# MDR1986VK214 register map
Vendor: Milandr; Series: ARMCM0; File version: 2.0
CPU: CM0 r0p0, little endian, no MPU, no FPU, 2 interrupt priority bits
Registers are 32-bit, read-write, reset 0x0 unless marked. A register's access mark holds for its fields unless they carry their own. Offsets are from the block's base; [hi:lo] are bit positions; {n}, {i} and the like mark numbered series; 'fields as' and 'values as' point back to an identical list.

## MDR_Power — Power Detector
Base 0x40058000
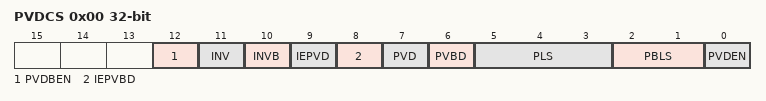
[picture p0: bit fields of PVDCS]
0x00 PVDCS — Control-Status register
  [12] PVDBEN — Enable BUcc detector
    0=Off (Disabled); 1=On (Enabled)
  [11] INV — PVD event on BUcc lt PBLS
    0=Off (Disabled); 1=On (Enabled)
  [10] INVB — PVBD event on BUcc lt PBLS
    0=Off (Disabled); 1=On (Enabled)
  [9] IEPVD — Enable IRQ by PVD event
    0=Off (Disabled); 1=On (Enabled)
  [8] IEPVBD — Enable IRQ by PVBD event
    0=Off (Disabled); 1=On (Enabled)
  [7] PVD — Event on Ucc gt PLS
    0=Inactive (No Event); 1=Active (Event is active)
  [6] PVBD — Event on BUcc gt PBLS
    0=Inactive (No Event); 1=Active (Event is active)
  [5:3] PLS — Ucc compare level
    0=2v0 (Level of 2.0 volts); 1=2v2 (Level of 2.2 volts); 2=2v4 (Level of 2.4 volts); 3=2v6 (Level of 2.6 volts); 4=2v8 (Level of 2.8 volts); 5=3v0 (Level of 3.0 volts); 6=3v2 (Level of 3.2 volts); 7=3v4 (Level of 3.4 volts)
  [2:1] PBLS — BUcc compare level
    0=1v8 (Level of 1.8 volts); 1=2v2 (Level of 2.2 volts); 2=2v6 (Level of 2.6 volts); 3=3v0 (Level of 3.0 volts)
  [0] PVDEN — Enable Ucc detector
    0=Off (Disabled); 1=On (Enabled)
0x04 ResReg ro reset not defined — Reserved register
  [31:0] Value — blank

## MDR_WWDT — Window Watchdog Timer
Base 0x40048000
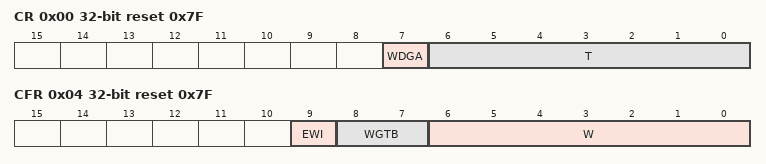
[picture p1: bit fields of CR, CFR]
0x00 CR reset 0x7F — WWDT Control register
  [7] WDGA — Enable
    0=Off (Disabled); 1=On (Enabled)
  [6:0] T — Counter
0x04 CFR reset 0x7F — WWDT Config register
  [9] EWI — Early Window Interrupt
    0=Off (Disabled IRQ on T=0x40); 1=On (Enabled IRQ on T=0x40)
  [8:7] WGTB — Clock Divider
    0=div1 (CLK = LSI/4096/1); 1=div2 (CLK = LSI/4096/2); 2=div4 (CLK = LSI/4096/4); 3=div8 (CLK = LSI/4096/8)
  [6:0] W — Window value
0x08 SR — WWDT Status register
  [0] EWIF — Early Window Flag
    0=Off (Event Off); 1=Onn (Event On)

## MDR_IWDT — Independent Watchdog Timer
Base 0x40050000
0x00 KR wo — Key register
  [15:0] KEY — Enable, start and reload control
0x04 PR — Clock Prescaler register
  [2:0] PR — Prescaler Register
    0=div4 (LSI div 4); 1=div8 (LSI div 8); 2=div16 (LSI div 16); 3=div32 (LSI div 32); 4=div64 (LSI div 64); 5=div128 (LSI div 128); 6=div256 (LSI div 256); 7=div256_1 (LSI div 256)
0x08 RLR reset 0xFFF — Reload Period Register
  [11:0] PRL — Timer Period Value
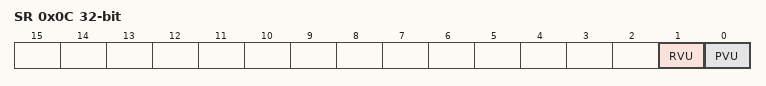
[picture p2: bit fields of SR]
0x0C SR ro — Status Regster
  [1] RVU — PRL busy
    0=Ready (PRL ready for write); 1=Busy (PRL busy)
  [0] PVU — PR busy
    0=Ready (PR ready for write); 1=Busy (PR busy)

## MDR_LCD_VK214 — LCD Display Controler
Base 0x40038000
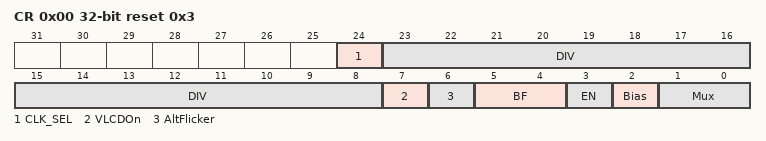
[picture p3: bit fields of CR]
0x00 CR reset 0x3 (reset mask 0xFFFFFF) — LCD Control register
  [24] CLK_SEL — Clock Select
    0=LSE (Clock from LSE); 1=LSI (Clock from LSI)
  [23:8] DIV — Clock div
  [7] VLCDOn — Select Vlcd power
    0=Internal source; 1=External source from pin PC2
  [6] AltFlicker — AlterFlicker
    0=byRegBF (Flicker according to BF); 1=byAlterMemory (Flicker according to alter memory)
  [5:4] BF — Flicker
    0=Off (Flicker Disabled); 1=2Hz (Flicker with 2 Hz); 2=1Hz (Flicker with 1 Hz); 3=0Hz5 (Flicker with 0.5 Hz)
  [3] EN — Enable
    0=Off (Disabled); 1=On (Enabled)
  [2] Bias — Bias Modes
    0=div3 (Bias 1/3); 1=div2 (Bias 1/2)
  [1:0] Mux — Multiplex select
    0=Static control; 1=Muxtiplexing 1:2; 2=Muxtiplexing 1:3; 3=Muxtiplexing 1:4
{0x0+4i} ROW{i} (i=1..4) (reset mask 0x3FFFFFFF) — Base memory data string
{0x10+4i} AROW{i} (i=1..4) (reset mask 0x3FFFFFFF) — Alter memory data string

## MDR_SSP1 — Synchronous Serial Port
Base 0x40000000
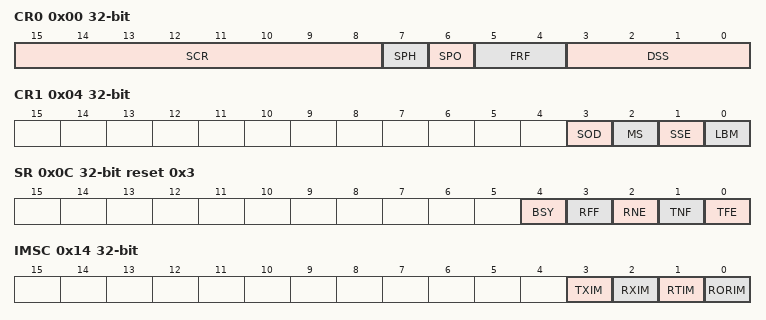
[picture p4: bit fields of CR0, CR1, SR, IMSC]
0x00 CR0 — Control Register 0
  [15:8] SCR — Signal CLock Rate
  [7] SPH — SPI Capture Clock Phase
    0=Leading (Capture data on leading edge); 1=Trailing (Capture data on trailing edge)
  [6] SPO — SPI Clock Polarity
    0=Idle_Low (Idle state is Low); 1=Idle_High (Idle state is High)
  [5:4] FRF — Frame Format
    0=SPI (Motorola SPI protocol); 1=SSI (Texas Instruments SSI protocol); 2=Microwire (National Semiconductor Microwire protocol)
  [3:0] DSS — Data Size Select
    {v}=bits_{v+1} (Word of {v+1} bits) (v=3..15)
0x04 CR1 — Control Register 1
  [3] SOD — Slave mode Output Disable
    0=SlaveTxEna (Slave mode transmit enable); 1=SlaveTxDis (Slave mode transmit disable)
  [2] MS — Master or Slave mode
    0=Master Mode; 1=Slave Mode
  [1] SSE — Synchronous Serial Enable
    0=Off (SSP Disable); 1=On (SSP Enable)
  [0] LBM — Loop Back Mode
    0=Normal operation; 1=LoopBack (TX send to RX test mode)
0x08 DR — FIFO_Rx and FIFO_Tx access
  [15:0] Data — Data value
0x0C SR ro reset 0x3 — Status Register
  [4] BSY — Transfer in progress
    0=Idle (FIFO_RX is Not Full); 1=Busy (Transfering)
  [3] RFF — FIFO_RX is Full
    0=RX_NotFull (FIFO_RX is Not Full); 1=RX_Full (FIFO_RX is Full)
  [2] RNE — FIFO_RX is Not Empty
    0=RX_NotEmpty (FIFO_RX is Empty); 1=RX_Empty (FIFO_RX is Not Empty)
  [1] TNF — FIFO_TX is Not Full
    0=TX_Full (FIFO_TX is Full); 1=TX_NotFull (FIFO_TX is Not Full)
  [0] TFE — FIFO_TX is Empty
    0=TX_NotEmpty (FIFO_TX is Not Empty); 1=TX_Empty (FIFO_TX is Empty)
0x10 CPSR — Clock Prescaller Register
  [7:0] CPSDVSR — Clock Prescaller
0x14 IMSC — IRQ Mask Set-Clear
  [3] TXIM — Enable IQR on FIFO_TX le 4 words
    0=NoEvent (Flag Inactive); 1=TX_HalfEmpty (Flag Active)
  [2] RXIM — Enable IQR on FIFO_RX ge 4 words
    0=NoEvent (Flag Inactive); 1=RX_HalfFull (Flag Active)
  [1] RTIM — Enable IQR on RX timeout for 32bits
    0=NoEvent (Flag Inactive); 1=RX_Timeout (Flag Active)
  [0] RORIM — Enable IRQ on FIFO_RX overrun
    0=NoEvent (Flag Inactive); 1=RX_Overrun (Flag Active)
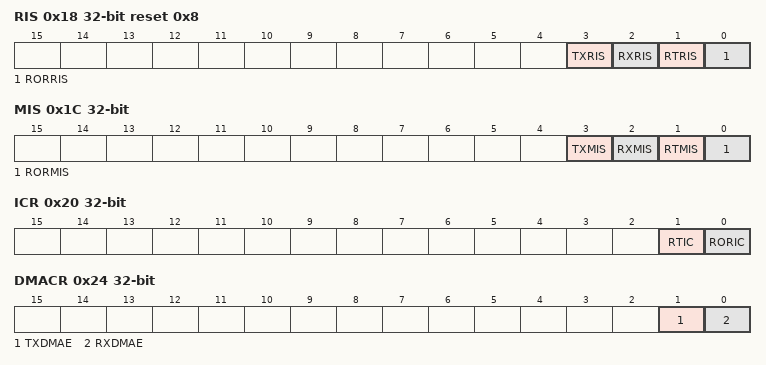
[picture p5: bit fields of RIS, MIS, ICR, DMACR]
0x18 RIS ro reset 0x8 — Raw Interupt Status
  [3] TXRIS — FIFO_TX le words
    0=NoEvent (Flag Inactive); 1=TX_HalfEmpty (Flag Active)
  [2] RXRIS — FIFO_RX gt words
    0=NoEvent (Flag Inactive); 1=RX_HalfFull (Flag Active)
  [1] RTRIS — RX timeout for 32bits
    0=NoEvent (Flag Inactive); 1=RX_Timeout (Flag Active)
  [0] RORRIS — FIFO_RX is overrun
    0=NoEvent (Flag Inactive); 1=RX_Overrun (Flag Active)
0x1C MIS ro — Masked Interupt Status
  [3] TXMIS — FIFO_TX le 4 words
    0=NoEvent (Flag Inactive); 1=TX_HalfEmpty (Flag Active)
  [2] RXMIS — FIFO_RX ge 4 words
    0=NoEvent (Flag Inactive); 1=RX_HalfFull (Flag Active)
  [1] RTMIS — RX timeout for 32bits
    0=NoEvent (Flag Inactive); 1=RX_Timeout (Flag Active)
  [0] RORMIS — FIFO_RX is overrun
    0=NoEvent (Flag Inactive); 1=RX_Overrun (Flag Active)
0x20 ICR wo — Interupt Clear Register
  [1] RTIC — Clear RX timeout flag
    0=Inactive (No action); 1=Clear Flag
  [0] RORIC — Clear FIFO_RX overrun flag
    0=Inactive (No action); 1=Clear Flag
0x24 DMACR — DMA Control Register
  [1] TXDMAE — Enable DMA by FIFO_TX not Full
    0=Disable DMA; 1=Enable DMA
  [0] RXDMAE — Enable DMA by FIFO_RX has data
    0=Disable DMA; 1=Enable DMA

## MDR_PORTA — GPIO Port Control
Base 0x40080000
Same registers: MDR_PORTB 0x40088000, MDR_PORTC 0x40090000
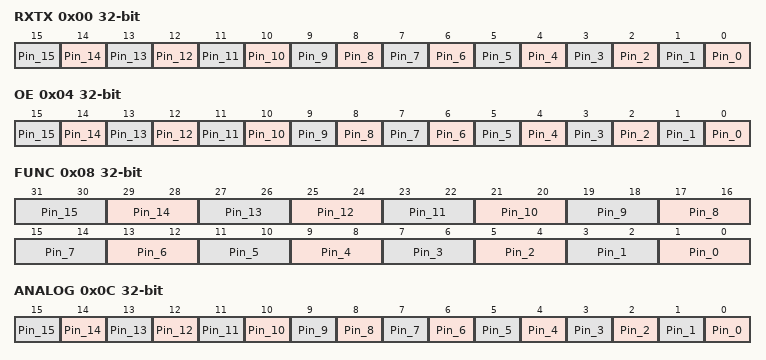
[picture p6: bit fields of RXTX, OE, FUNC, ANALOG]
0x00 RXTX (reset mask 0xFFFF) — GPIO Pin Data
  [n] Pin_{n} (n=0..15) — Pin data value
    0=Low (LOW Level Voltage); 1=HIGH Level Voltage
0x04 OE (reset mask 0xFFFF) — Output Enable Control
  [n] Pin_{n} (n=0..15) — Pin data direction
    0=IN (Input pin); 1=OUT (Output pin)
0x08 FUNC — Pin Functions in Digital mode
  [2n+1:2n] Pin_{n} (n=0..15) — Pin Digital Function
    0=Port (RXTX defined pin); 1=Main Periph defined pin; 2=Alter Periph defined pin; 3=Override Periph defined pin
0x0C ANALOG (reset mask 0xFFFF) — Enable Digital Mode Control
  [n] Pin_{n} (n=0..15) — Enable Digital mode
    0=Analog (Pin works with Analog signal); 1=Digital (Pin works with Digital signal)
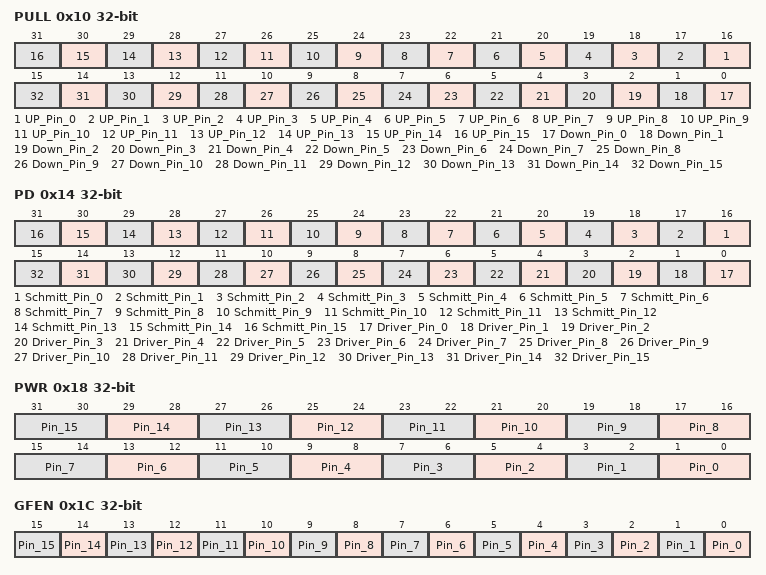
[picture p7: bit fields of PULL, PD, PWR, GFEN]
0x10 PULL — PULL Up and Down Control
  [n+16] UP_Pin_{n} (n=0..15) — Pull Up Enable
    0=Off (No pull selected); 1=UP (Pin pulled up to Ucc)
  [n] Down_Pin_{n} (n=0..15) — Pull Down Enable
    0=Off (No pull selected); 1=DOWN (Pin pulled down to GND)
0x14 PD — Otput Driver Mode
  [n+16] Schmitt_Pin_{n} (n=0..15) — Schmitt trigger enable
    0=Off (Schmitt 200mv); 1=On (Schmitt 400mv)
  [n] Driver_Pin_{n} (n=0..15) — Driver mode for pin
    0=Driver (Pull-Push driver); 1=OpenDrain (Work with line pulled up to Ucc)
0x18 PWR — Output voltage switch rate
  [2n+1:2n] Pin_{n} (n=0..15) — Voltage levels switch rate
    0=Off (Level switch disabled); 1=Slow (Levels switch rate about 100ns); 2=Fast (Levels switch rate about 20ns); 3=MaxFast (Levels switch rate about 10ns)
0x1C GFEN (reset mask 0xFFFF) — Input pulses filter
  [n] Pin_{n} (n=0..15) — Filter for pin
    0=Off (Filter Off); 1=On (Filter pulses less then 10 ns)
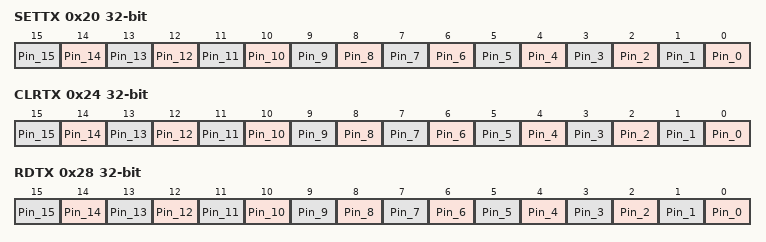
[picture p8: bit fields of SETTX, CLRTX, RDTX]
0x20 SETTX (reset mask 0xFFFF) write-1-sets — Set RXTX by MASK
  [n] Pin_{n} (n=0..15) — Set 1 to pin
    0=Inactive (Do nothing); 1=Selected (Set High level to pin with reg RXTX)
0x24 CLRTX (reset mask 0xFFFF) write-1-clears — CLR RXTX by MASK
  [n] Pin_{n} (n=0..15) — Clear pin to 0
    0=Inactive (Do nothing); 1=Selected (Set Low level to pin with reg RXTX)
0x28 RDTX ro (reset mask 0xFFFF) — Value of RXTX in Port mode
  fields as RXTX
